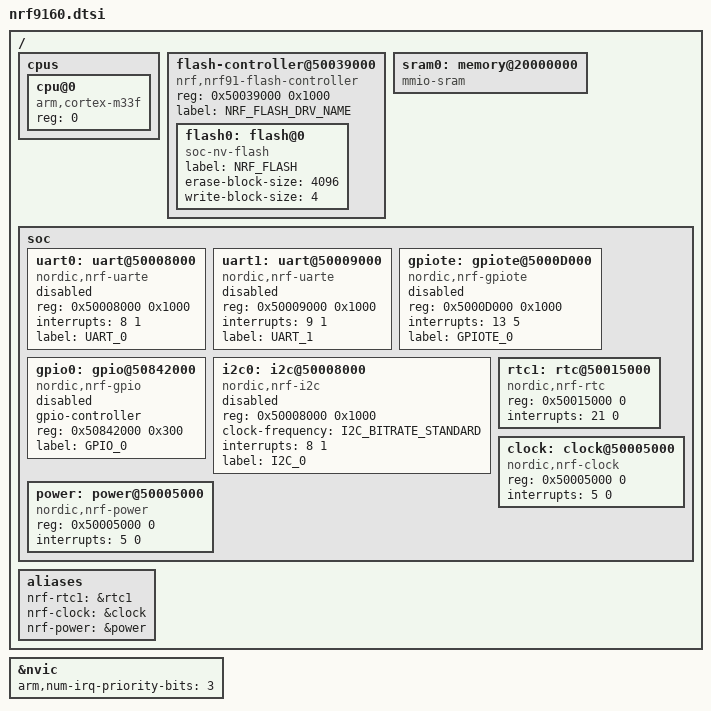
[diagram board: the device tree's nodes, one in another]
#include <arm/armv8-m.dtsi>
#include <dt-bindings/gpio/gpio.h>
#include <dt-bindings/i2c/i2c.h>
/ {
	cpus {
		#address-cells = <1>;
		#size-cells = <0>;

		cpu@0 {
			device_type = "cpu";
			compatible = "arm,cortex-m33f";
			reg = <0>;
		};
	};

	flash-controller@50039000 {
			compatible = "nrf,nrf91-flash-controller";
			reg = <0x50039000 0x1000>;

			#address-cells = <1>;
			#size-cells = <1>;

			label="NRF_FLASH_DRV_NAME";

			flash0: flash@0 {
				compatible = "soc-nv-flash";
				label = "NRF_FLASH";
				erase-block-size = <4096>;
				write-block-size = <4>;
			};
	};

	sram0: memory@20000000 {
		device_type = "memory";
		compatible = "mmio-sram";
	};

	soc {
		uart0: uart@50008000 {
			compatible = "nordic,nrf-uarte";
			reg = <0x50008000 0x1000>;
			interrupts = <8 1>;
			status = "disabled";
			label = "UART_0";
		};

		uart1: uart@50009000 {
			compatible = "nordic,nrf-uarte";
			reg = <0x50009000 0x1000>;
			interrupts = <9 1>;
			status = "disabled";
			label = "UART_1";
		};

		gpiote: gpiote@5000D000 {
			compatible = "nordic,nrf-gpiote";
			reg = <0x5000D000 0x1000>;
			interrupts = <13 5>;
			interrupt-names = "gpiote";
			status = "disabled";
			label = "GPIOTE_0";
		};

		gpio0: gpio@50842000 {
			compatible = "nordic,nrf-gpio";
			gpio-controller;
			reg = <0x50842000 0x300>;
			#gpio-cells = <2>;
			label = "GPIO_0";
			status = "disabled";
		};

		i2c0: i2c@50008000 {
			compatible = "nordic,nrf-i2c";
			#address-cells = <1>;
			#size-cells = <0>;
			reg = <0x50008000 0x1000>;
			clock-frequency = <I2C_BITRATE_STANDARD>;
			interrupts = <8 1>;
			status = "disabled";
			label = "I2C_0";
		};

		rtc1: rtc@50015000 {
			compatible = "nordic,nrf-rtc";
			reg = <0x50015000 0>;
			interrupts = <21 0>;
			status = "ok";
		};

		clock: clock@50005000 {
			compatible = "nordic,nrf-clock";
			reg = <0x50005000 0>;
			interrupts = <5 0>;
			status = "ok";
		};

		power: power@50005000 {
			compatible = "nordic,nrf-power";
			reg = <0x50005000 0>;
			interrupts = <5 0>;
			status = "ok";
		};
	};
	aliases {
		nrf-rtc1 = &rtc1;
		nrf-clock = &clock;
		nrf-power = &power;
	};
};

&nvic {
	arm,num-irq-priority-bits = <3>;
};
